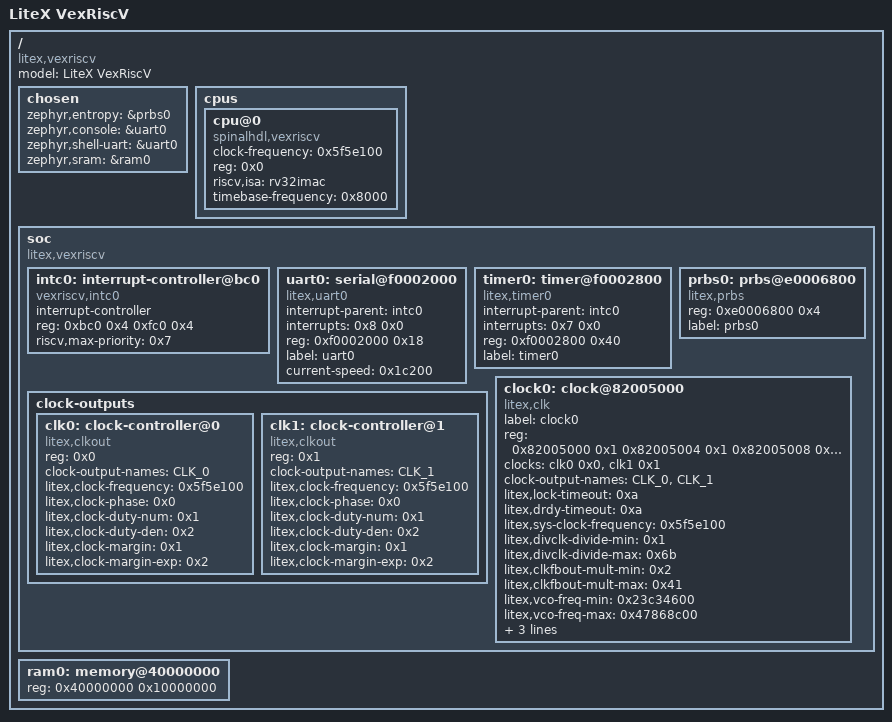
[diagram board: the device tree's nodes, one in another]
/dts-v1/;

/ {
	#address-cells = < 0x1 >;
	#size-cells = < 0x1 >;
	compatible = "litex,vexriscv";
	model = "LiteX VexRiscV";
	chosen {
		zephyr,entropy = &prbs0;
		zephyr,console = &uart0;
		zephyr,shell-uart = &uart0;
		zephyr,sram = &ram0;
	};
	cpus {
		#address-cells = < 0x1 >;
		#size-cells = < 0x0 >;
		cpu@0 {
			clock-frequency = < 0x5f5e100 >;
			compatible = "spinalhdl,vexriscv", "riscv";
			device_type = "cpu";
			reg = < 0x0 >;
			riscv,isa = "rv32imac";
			status = "okay";
			timebase-frequency = < 0x8000 >;
		};
	};
	soc {
		#address-cells = < 0x1 >;
		#size-cells = < 0x1 >;
		compatible = "litex,vexriscv";
		ranges;
		intc0: interrupt-controller@bc0 {
			#interrupt-cells = < 0x2 >;
			compatible = "vexriscv,intc0";
			interrupt-controller;
			reg = < 0xbc0 0x4 0xfc0 0x4 >;
			reg-names = "irq_mask", "irq_pending";
			riscv,max-priority = < 0x7 >;
			phandle = < 0x1 >;
		};
		uart0: serial@f0002000 {
			compatible = "litex,uart0";
			interrupt-parent = < &intc0 >;
			interrupts = < 0x8 0x0 >;
			reg = < 0xf0002000 0x18 >;
			reg-names = "control";
			label = "uart0";
			status = "okay";
			current-speed = < 0x1c200 >;
		};
		timer0: timer@f0002800 {
			compatible = "litex,timer0";
			interrupt-parent = < &intc0 >;
			interrupts = < 0x7 0x0 >;
			reg = < 0xf0002800 0x40 >;
			reg-names = "control";
			label = "timer0";
			status = "okay";
		};
		prbs0: prbs@e0006800 {
			compatible = "litex,prbs";
			reg = < 0xe0006800 0x4 >;
			reg-names = "status";
			label = "prbs0";
			status = "okay";
		};
		clock-outputs {
			#address-cells = < 0x1 >;
			#size-cells = < 0x0 >;
			clk0: clock-controller@0 {
				#clock-cells = < 0x1 >;
				reg = < 0x0 >;
				compatible = "litex,clkout";
				clock-output-names = "CLK_0";
				litex,clock-frequency = < 0x5f5e100 >;
				litex,clock-phase = < 0x0 >;
				litex,clock-duty-num = < 0x1 >;
				litex,clock-duty-den = < 0x2 >;
				litex,clock-margin = < 0x1 >;
				litex,clock-margin-exp = < 0x2 >;
				status = "okay";
				phandle = < 0x2 >;
			};
			clk1: clock-controller@1 {
				#clock-cells = < 0x1 >;
				reg = < 0x1 >;
				compatible = "litex,clkout";
				clock-output-names = "CLK_1";
				litex,clock-frequency = < 0x5f5e100 >;
				litex,clock-phase = < 0x0 >;
				litex,clock-duty-num = < 0x1 >;
				litex,clock-duty-den = < 0x2 >;
				litex,clock-margin = < 0x1 >;
				litex,clock-margin-exp = < 0x2 >;
				status = "okay";
				phandle = < 0x3 >;
			};
		};
		clock0: clock@82005000 {
			compatible = "litex,clk";
			label = "clock0";
			reg = < 0x82005000 0x1 0x82005004 0x1 0x82005008 0x1 0x8200500c 0x1 0x82005010 0x1 0x82005014 0x1 0x82005018 0x2 0x82005020 0x2 >;
			reg-names = "drp_reset", "drp_locked", "drp_read", "drp_write", "drp_drdy", "drp_adr", "drp_dat_w", "drp_dat_r";
			#clock-cells = < 0x1 >;
			#address-cells = < 0x1 >;
			#size-cells = < 0x1 >;
			clocks = < &clk0 0x0 >, < &clk1 0x1 >;
			clock-output-names = "CLK_0", "CLK_1";
			litex,lock-timeout = < 0xa >;
			litex,drdy-timeout = < 0xa >;
			litex,sys-clock-frequency = < 0x5f5e100 >;
			litex,divclk-divide-min = < 0x1 >;
			litex,divclk-divide-max = < 0x6b >;
			litex,clkfbout-mult-min = < 0x2 >;
			litex,clkfbout-mult-max = < 0x41 >;
			litex,vco-freq-min = < 0x23c34600 >;
			litex,vco-freq-max = < 0x47868c00 >;
			litex,clkout-divide-min = < 0x1 >;
			litex,clkout-divide-max = < 0x7e >;
			litex,vco-margin = < 0x0 >;
			status = "okay";
		};
	};
	ram0: memory@40000000 {
		device_type = "memory";
		reg = < 0x40000000 0x10000000 >;
	};
};
